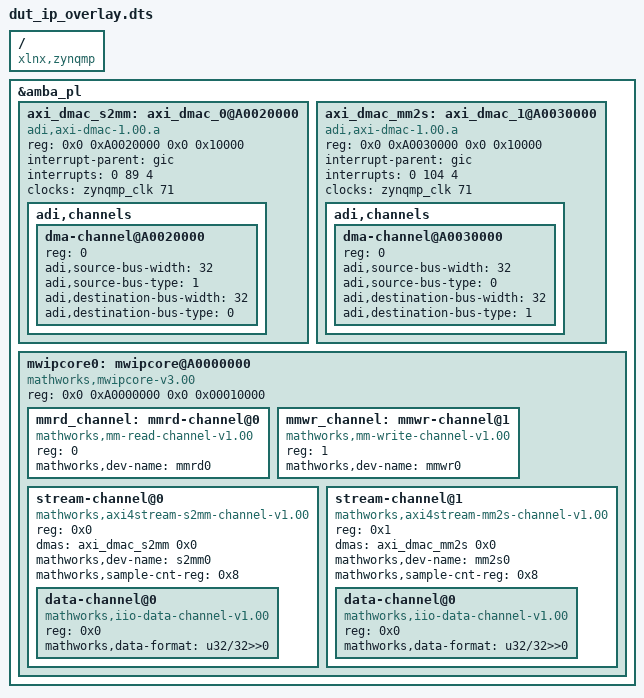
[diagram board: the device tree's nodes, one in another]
/dts-v1/;
/plugin/;

/ {
    compatible = "xlnx,zynqmp";

    /* Add everything under the existing PL bus */
    fragment@0 {
        target = <&amba_pl>;            /* __symbols__ exposes &amba_pl = "/amba_pl@0" */
        __overlay__ {
			#address-cells = <0x2>;
			#size-cells = <0x2>;

	axi_dmac_s2mm: axi_dmac_0@A0020000 {
				compatible   = "adi,axi-dmac-1.00.a";
                status       = "okay";
                reg          = <0x0 0xA0020000 0x0 0x10000>;
				
                #dma-cells = <1>;               

				interrupt-parent = <&gic>;
				interrupts = <0 89 4>;
				clocks       = <&zynqmp_clk 71>;
				
			adi,channels {
					#size-cells = <0>;
					#address-cells = <1>;
					dma-channel@A0020000 {						 
						reg = <0>;
						adi,source-bus-width = <32>;
						adi,source-bus-type = <1>;
						adi,destination-bus-width = <32>;
						adi,destination-bus-type = <0>;

					};
				};
			};
			
	axi_dmac_mm2s: axi_dmac_1@A0030000 {
				compatible   = "adi,axi-dmac-1.00.a";
                status       = "okay";
                reg          = <0x0 0xA0030000 0x0 0x10000>;
				
                #dma-cells = <1>;               

				interrupt-parent = <&gic>;
				interrupts = <0 104 4>;
				clocks       = <&zynqmp_clk 71>;
				
			adi,channels {
					#size-cells = <0>;
					#address-cells = <1>;
					dma-channel@A0030000 {						 
						reg = <0>;
						adi,source-bus-width = <32>;
						adi,source-bus-type = <0>;
						adi,destination-bus-width = <32>;
						adi,destination-bus-type = <1>;

					};
				};
			};
			
			
			
			

            /* MathWorks IP + channels */
            mwipcore0: mwipcore@A0000000 {
                compatible      = "mathworks,mwipcore-v3.00";
                reg             = <0x0 0xA0000000 0x0 0x00010000>;
                #address-cells  = <1>;
                #size-cells     = <0>;

                /* AXI4-Lite accessors */
                mmrd_channel: mmrd-channel@0 {
                    reg = <0>;
                    compatible = "mathworks,mm-read-channel-v1.00";
                    mathworks,dev-name = "mmrd0";
                };

                mmwr_channel: mmwr-channel@1 {
                    reg = <1>;
                    compatible = "mathworks,mm-write-channel-v1.00";
                    mathworks,dev-name = "mmwr0";
                };

                /* AXI4-Stream S2MM path */

				// Device tree node for read channel of interface "AXI4-Stream"
				stream-channel@0 {
					reg = <0x0>;
					compatible = "mathworks,axi4stream-s2mm-channel-v1.00";
					dma-names = "s2mm";
					dmas = <&axi_dmac_s2mm 0x0>;
					mathworks,dev-name = "s2mm0";
					mathworks,sample-cnt-reg = <0x8>;
					data-channel@0 {
						reg = <0x0>;
						compatible = "mathworks,iio-data-channel-v1.00";
						mathworks,data-format = "u32/32>>0";
					};
                };
				stream-channel@1 {
					reg = <0x1>;

					compatible = "mathworks,axi4stream-mm2s-channel-v1.00";
					dma-names = "mm2s";
					dmas = <&axi_dmac_mm2s 0x0>;
					mathworks,dev-name = "mm2s0";
					mathworks,sample-cnt-reg = <0x8>;
					data-channel@0 {
						reg = <0x0>;
						compatible = "mathworks,iio-data-channel-v1.00";
						mathworks,data-format = "u32/32>>0";
					};
                };
            };
        };
    };
};
